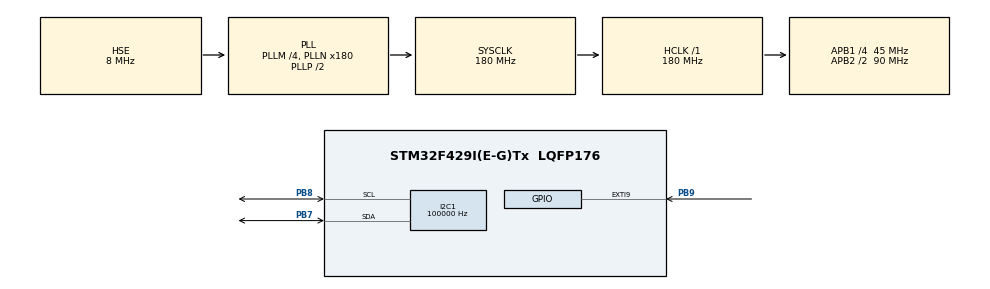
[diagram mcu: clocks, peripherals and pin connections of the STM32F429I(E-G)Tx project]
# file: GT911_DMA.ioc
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DMA2D.AlphaModeForeground=DMA2D_COMBINE_ALPHA
DMA2D.ColorMode=DMA2D_OUTPUT_RGB565
Dma.I2C1_RX.0.Direction=DMA_PERIPH_TO_MEMORY
Dma.I2C1_RX.0.FIFOMode=DMA_FIFOMODE_DISABLE
Dma.I2C1_RX.0.Instance=DMA1_Stream0
Dma.I2C1_RX.0.MemDataAlignment=DMA_MDATAALIGN_BYTE
Dma.I2C1_RX.0.MemInc=DMA_MINC_ENABLE
Dma.I2C1_RX.0.Mode=DMA_NORMAL
Dma.I2C1_RX.0.PeriphDataAlignment=DMA_PDATAALIGN_BYTE
Dma.I2C1_RX.0.PeriphInc=DMA_PINC_DISABLE
Dma.I2C1_RX.0.Priority=DMA_PRIORITY_LOW
Dma.I2C1_TX.1.Direction=DMA_MEMORY_TO_PERIPH
Dma.I2C1_TX.1.FIFOMode=DMA_FIFOMODE_DISABLE
Dma.I2C1_TX.1.Instance=DMA1_Stream6
Dma.I2C1_TX.1.MemDataAlignment=DMA_MDATAALIGN_BYTE
Dma.I2C1_TX.1.MemInc=DMA_MINC_ENABLE
Dma.I2C1_TX.1.Mode=DMA_NORMAL
Dma.I2C1_TX.1.PeriphDataAlignment=DMA_PDATAALIGN_BYTE
Dma.I2C1_TX.1.PeriphInc=DMA_PINC_DISABLE
Dma.I2C1_TX.1.Priority=DMA_PRIORITY_LOW
Dma.Request0=I2C1_RX
Dma.Request1=I2C1_TX
I2C1.ClockSpeed=100000
Mcu.Family=STM32F4
Mcu.Name=STM32F429I(E-G)Tx
Mcu.Package=LQFP176
NVIC.DMA1_Stream0_IRQn=true\:0\:0\:false\:false\:true\:false\:true
NVIC.DMA1_Stream6_IRQn=true\:0\:0\:false\:false\:true\:false\:true
NVIC.EXTI9_5_IRQn=true\:0\:0\:false\:false\:true\:true\:true
NVIC.I2C1_EV_IRQn=true\:0\:0\:false\:false\:true\:true\:true
NVIC.PriorityGroup=NVIC_PRIORITYGROUP_4
PA13.Mode=Serial_Wire
PA13.Signal=SYS_JTMS-SWDIO
PA14.Mode=Serial_Wire
PA14.Signal=SYS_JTCK-SWCLK
PB7.Mode=I2C
PB7.Signal=I2C1_SDA
PB8.Mode=I2C
PB8.Signal=I2C1_SCL
PB9.Signal=GPXTI9
PH0/OSC_IN.Mode=HSE-External-Oscillator
PH0/OSC_IN.Signal=RCC_OSC_IN
PH1/OSC_OUT.Mode=HSE-External-Oscillator
PH1/OSC_OUT.Signal=RCC_OSC_OUT
ProjectManager.HeapSize=0x200
ProjectManager.StackSize=0x400
ProjectManager.TargetToolchain=STM32CubeIDE
RCC.48MHZClocksFreq_Value=90000000
RCC.AHBFreq_Value=180000000
RCC.APB1CLKDivider=RCC_HCLK_DIV4
RCC.APB1Freq_Value=45000000
RCC.APB1TimFreq_Value=90000000
RCC.APB2CLKDivider=RCC_HCLK_DIV2
RCC.APB2Freq_Value=90000000
RCC.APB2TimFreq_Value=180000000
RCC.CortexFreq_Value=180000000
RCC.HCLKFreq_Value=180000000
RCC.HSE_VALUE=8000000
RCC.HSI_VALUE=16000000
RCC.LSE_VALUE=32768
RCC.PLLM=4
RCC.PLLN=180
RCC.PLLSourceVirtual=RCC_PLLSOURCE_HSE
RCC.SYSCLKFreq_VALUE=180000000
RCC.SYSCLKSource=RCC_SYSCLKSOURCE_PLLCLK
RCC.VCOOutputFreq_Value=360000000
VP_CRC_VS_CRC.Mode=CRC_Activate
VP_DMA2D_VS_DMA2D.Mode=DMA2D_Activate
board=custom

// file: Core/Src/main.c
/* USER CODE BEGIN Header */
/**
  ******************************************************************************
  * @file           : main.c
  * @brief          : Main program body
  ******************************************************************************
  * @attention
  *
  * <h2><center>&copy; Copyright (c) 2023 STMicroelectronics.
  * All rights reserved.</center></h2>
  *
  * This software component is licensed by ST under BSD 3-Clause license,
  * the "License"; You may not use this file except in compliance with the
  * License. You may obtain a copy of the License at:
  *                        opensource.org/licenses/BSD-3-Clause
  *
  ******************************************************************************
  */
/* USER CODE END Header */

#include "main.h"

/* USER CODE BEGIN Includes */
#include "GT911.h"
/* USER CODE END Includes */

CRC_HandleTypeDef hcrc;

DMA2D_HandleTypeDef hdma2d;

I2C_HandleTypeDef hi2c1;
DMA_HandleTypeDef hdma_i2c1_rx;
DMA_HandleTypeDef hdma_i2c1_tx;

void SystemClock_Config(void);
static void MX_GPIO_Init(void);
static void MX_DMA_Init(void);
static void MX_CRC_Init(void);
static void MX_DMA2D_Init(void);
static void MX_I2C1_Init(void);

int main(void)
{

  /* MCU Configuration--------------------------------------------------------*/

  /* Reset of all peripherals, Initializes the Flash interface and the Systick. */
  HAL_Init();

  /* Configure the system clock */
  SystemClock_Config();

  /* Initialize all configured peripherals */
  MX_GPIO_Init();
  MX_DMA_Init();
  MX_CRC_Init();
  MX_DMA2D_Init();
  MX_I2C1_Init();
  /* USER CODE BEGIN 2 */
  GT911_init();
  /* USER CODE END 2 */

  /* Infinite loop */
  while (1)
  {

  }
}

void SystemClock_Config(void)
{
  RCC_OscInitTypeDef RCC_OscInitStruct = {0};
  RCC_ClkInitTypeDef RCC_ClkInitStruct = {0};

  /** Configure the main internal regulator output voltage
  */
  __HAL_RCC_PWR_CLK_ENABLE();
  __HAL_PWR_VOLTAGESCALING_CONFIG(PWR_REGULATOR_VOLTAGE_SCALE1);
  /** Initializes the CPU, AHB and APB busses clocks
  */
  RCC_OscInitStruct.OscillatorType = RCC_OSCILLATORTYPE_HSE;
  RCC_OscInitStruct.HSEState = RCC_HSE_ON;
  RCC_OscInitStruct.PLL.PLLState = RCC_PLL_ON;
  RCC_OscInitStruct.PLL.PLLSource = RCC_PLLSOURCE_HSE;
  RCC_OscInitStruct.PLL.PLLM = 4;
  RCC_OscInitStruct.PLL.PLLN = 180;
  RCC_OscInitStruct.PLL.PLLP = RCC_PLLP_DIV2;
  RCC_OscInitStruct.PLL.PLLQ = 4;
  if (HAL_RCC_OscConfig(&RCC_OscInitStruct) != HAL_OK)
  {
    Error_Handler();
  }
  /** Activate the Over-Drive mode
  */
  if (HAL_PWREx_EnableOverDrive() != HAL_OK)
  {
    Error_Handler();
  }
  /** Initializes the CPU, AHB and APB busses clocks
  */
  RCC_ClkInitStruct.ClockType = RCC_CLOCKTYPE_HCLK|RCC_CLOCKTYPE_SYSCLK
                              |RCC_CLOCKTYPE_PCLK1|RCC_CLOCKTYPE_PCLK2;
  RCC_ClkInitStruct.SYSCLKSource = RCC_SYSCLKSOURCE_PLLCLK;
  RCC_ClkInitStruct.AHBCLKDivider = RCC_SYSCLK_DIV1;
  RCC_ClkInitStruct.APB1CLKDivider = RCC_HCLK_DIV4;
  RCC_ClkInitStruct.APB2CLKDivider = RCC_HCLK_DIV2;

  if (HAL_RCC_ClockConfig(&RCC_ClkInitStruct, FLASH_LATENCY_5) != HAL_OK)
  {
    Error_Handler();
  }
}

static void MX_CRC_Init(void)
{

  hcrc.Instance = CRC;
  if (HAL_CRC_Init(&hcrc) != HAL_OK)
  {
    Error_Handler();
  }

}

static void MX_DMA2D_Init(void)
{

  hdma2d.Instance = DMA2D;
  hdma2d.Init.Mode = DMA2D_M2M;
  hdma2d.Init.ColorMode = DMA2D_OUTPUT_RGB565;
  hdma2d.Init.OutputOffset = 0;
  hdma2d.LayerCfg[1].InputOffset = 0;
  hdma2d.LayerCfg[1].InputColorMode = DMA2D_INPUT_RGB565;
  hdma2d.LayerCfg[1].AlphaMode = DMA2D_COMBINE_ALPHA;
  hdma2d.LayerCfg[1].InputAlpha = 0;
  if (HAL_DMA2D_Init(&hdma2d) != HAL_OK)
  {
    Error_Handler();
  }
  if (HAL_DMA2D_ConfigLayer(&hdma2d, 1) != HAL_OK)
  {
    Error_Handler();
  }

}

static void MX_I2C1_Init(void)
{

  hi2c1.Instance = I2C1;
  hi2c1.Init.ClockSpeed = 100000;
  hi2c1.Init.DutyCycle = I2C_DUTYCYCLE_2;
  hi2c1.Init.OwnAddress1 = 0;
  hi2c1.Init.AddressingMode = I2C_ADDRESSINGMODE_7BIT;
  hi2c1.Init.DualAddressMode = I2C_DUALADDRESS_DISABLE;
  hi2c1.Init.OwnAddress2 = 0;
  hi2c1.Init.GeneralCallMode = I2C_GENERALCALL_DISABLE;
  hi2c1.Init.NoStretchMode = I2C_NOSTRETCH_DISABLE;
  if (HAL_I2C_Init(&hi2c1) != HAL_OK)
  {
    Error_Handler();
  }
  /** Configure Analogue filter
  */
  if (HAL_I2CEx_ConfigAnalogFilter(&hi2c1, I2C_ANALOGFILTER_ENABLE) != HAL_OK)
  {
    Error_Handler();
  }
  /** Configure Digital filter
  */
  if (HAL_I2CEx_ConfigDigitalFilter(&hi2c1, 0) != HAL_OK)
  {
    Error_Handler();
  }

}

static void MX_DMA_Init(void)
{

  /* DMA controller clock enable */
  __HAL_RCC_DMA1_CLK_ENABLE();

  /* DMA interrupt init */
  /* DMA1_Stream0_IRQn interrupt configuration */
  HAL_NVIC_SetPriority(DMA1_Stream0_IRQn, 0, 0);
  HAL_NVIC_EnableIRQ(DMA1_Stream0_IRQn);
  /* DMA1_Stream6_IRQn interrupt configuration */
  HAL_NVIC_SetPriority(DMA1_Stream6_IRQn, 0, 0);
  HAL_NVIC_EnableIRQ(DMA1_Stream6_IRQn);

}

static void MX_GPIO_Init(void)
{
  GPIO_InitTypeDef GPIO_InitStruct = {0};

  /* GPIO Ports Clock Enable */
  __HAL_RCC_GPIOH_CLK_ENABLE();
  __HAL_RCC_GPIOA_CLK_ENABLE();
  __HAL_RCC_GPIOB_CLK_ENABLE();

  /*Configure GPIO pin : PB9 */
  GPIO_InitStruct.Pin = GPIO_PIN_9;
  GPIO_InitStruct.Mode = GPIO_MODE_IT_RISING;
  GPIO_InitStruct.Pull = GPIO_NOPULL;
  HAL_GPIO_Init(GPIOB, &GPIO_InitStruct);

  /* EXTI interrupt init*/
  HAL_NVIC_SetPriority(EXTI9_5_IRQn, 0, 0);
  HAL_NVIC_EnableIRQ(EXTI9_5_IRQn);

}

void Error_Handler(void)
{
}

/************************ (C) COPYRIGHT STMicroelectronics *****END OF FILE****/
